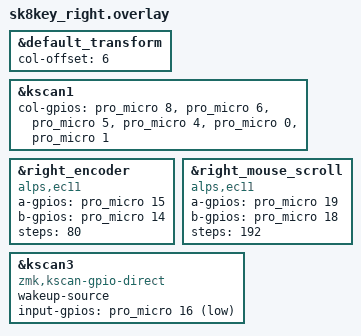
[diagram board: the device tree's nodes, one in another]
#include "sk8key.dtsi"

&default_transform {
    col-offset = <6>;
};

&kscan1 {
    col-gpios

        = <&pro_micro 8 GPIO_ACTIVE_HIGH>   // Mod → P104
        , <&pro_micro 6 GPIO_ACTIVE_HIGH>   // Inner → P100
        , <&pro_micro 5 GPIO_ACTIVE_HIGH>   // Index → P024
        , <&pro_micro 4 GPIO_ACTIVE_HIGH>   // Middle → P022
        , <&pro_micro 0 GPIO_ACTIVE_HIGH>   // Ring → P008
        , <&pro_micro 1 GPIO_ACTIVE_HIGH>   // Pinky → P006
        ;

};

&right_encoder     {
    compatible = "alps,ec11";
    a-gpios = <&pro_micro 15 (GPIO_ACTIVE_HIGH | GPIO_PULL_UP)>;
    b-gpios = <&pro_micro 14 (GPIO_ACTIVE_HIGH | GPIO_PULL_UP)>;
    steps = <80>;
    status = "okay";
};

&right_mouse_scroll {
    compatible = "alps,ec11";
    a-gpios = <&pro_micro 19 (GPIO_ACTIVE_HIGH | GPIO_PULL_UP)>;
    b-gpios = <&pro_micro 18 (GPIO_ACTIVE_HIGH | GPIO_PULL_UP)>;
    steps = <192>;
    status = "okay";
};

&kscan3 {
    compatible = "zmk,kscan-gpio-direct";
    wakeup-source;
    input-gpios
        = <&pro_micro 16 (GPIO_ACTIVE_LOW | GPIO_PULL_UP)>
        ;
 };


